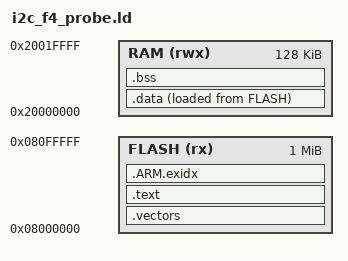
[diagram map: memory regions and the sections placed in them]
MEMORY
{
    FLASH (rx) : ORIGIN = 0x08000000, LENGTH = 1024K
    RAM (rwx) : ORIGIN = 0x20000000, LENGTH = 128K
}
SECTIONS
{
    .vectors : { KEEP(*(.vectors)) } > FLASH
    .text : { *(.text*) *(.rodata*) } > FLASH
    .ARM.exidx : { *(.ARM.exidx*) } > FLASH
    .data :
    {
        . = ALIGN(4);
        __data_start = .;
        *(.data*)
        . = ALIGN(4);
        __data_end = .;
    } > RAM AT > FLASH
    __data_load = LOADADDR(.data);
    .bss (NOLOAD) :
    {
        . = ALIGN(4);
        __bss_start = .;
        *(.bss*) *(COMMON)
        . = ALIGN(4);
        __bss_end = .;
    } > RAM
    /DISCARD/ : { *(.comment) *(.note*) }
}
